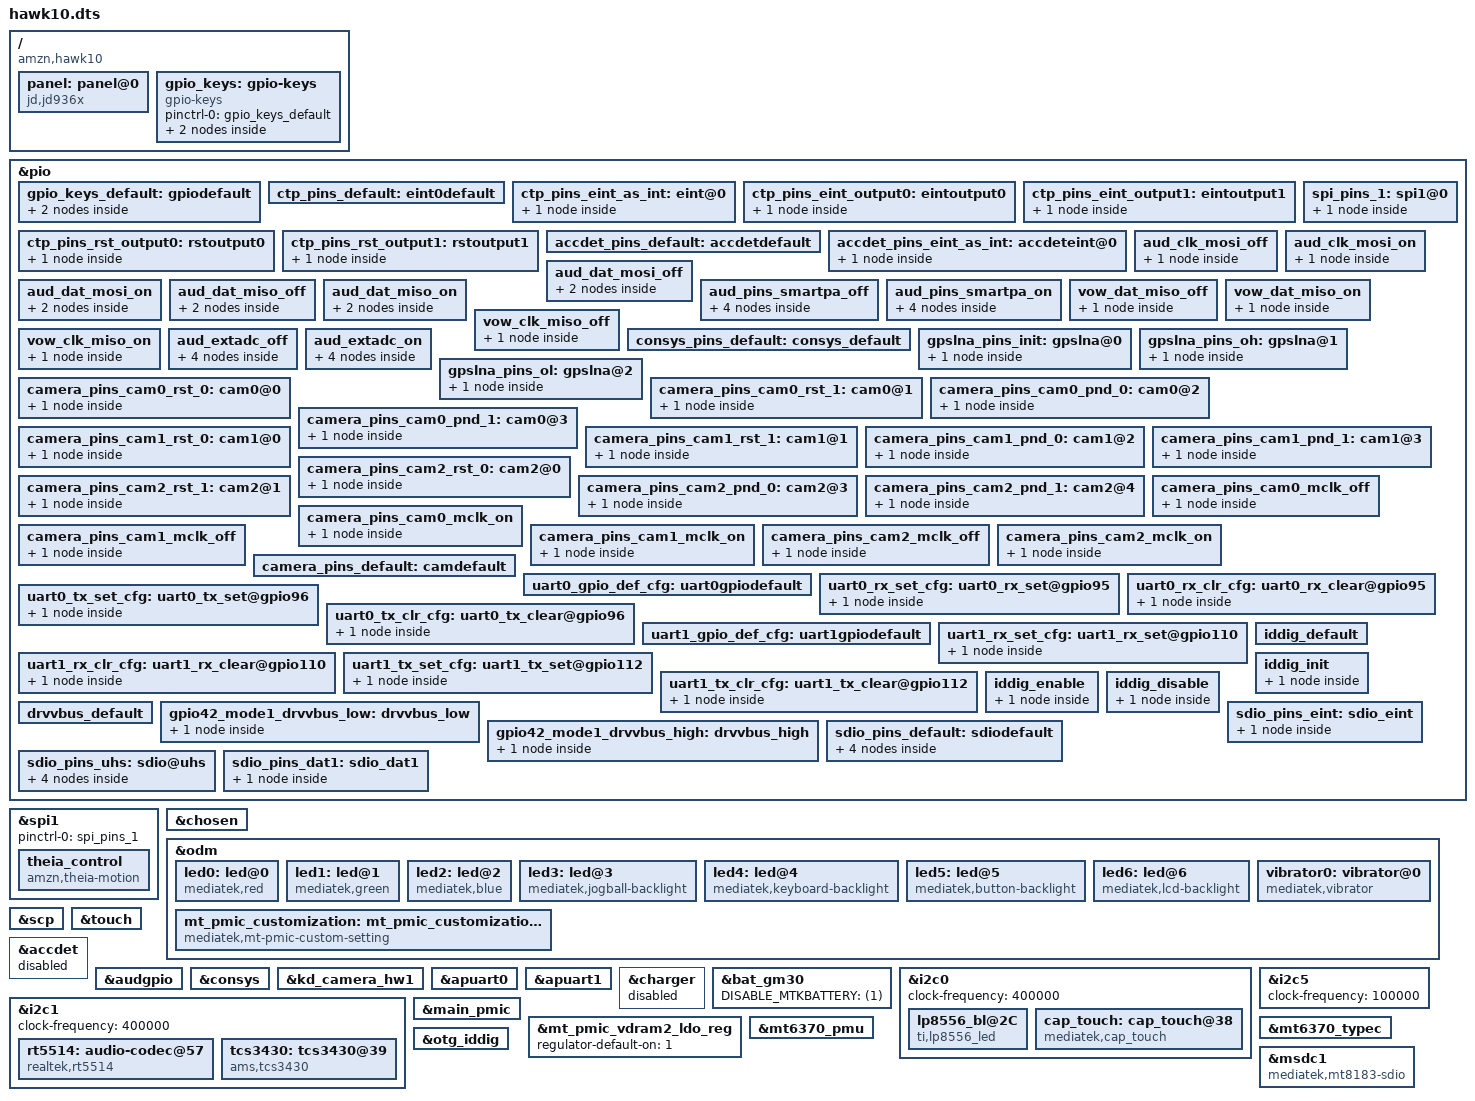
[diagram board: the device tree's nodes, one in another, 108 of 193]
/*
 * Copyright (C) 2018 MediaTek Inc.
 *
 * This program is free software; you can redistribute it and/or modify
 * it under the terms of the GNU General Public License version 2 as
 * published by the Free Software Foundation.
 *
 * This program is distributed in the hope that it will be useful,
 * but WITHOUT ANY WARRANTY; without even the implied warranty of
 * MERCHANTABILITY or FITNESS FOR A PARTICULAR PURPOSE.  See the
 * GNU General Public License for more details.  */

#include "mt8183.dts"
#include <hawk10/cust.dtsi>
#include <dt-bindings/clock/mt8183-clk.h>

/ {
	compatible = "amzn,hawk10";

	panel: panel@0 {
		compatible = "jd,jd936x";
		gpio_lcd_rst = <&pio 159 0>;
		gpio_bias_en = <&pio 176 0>;
		gpio_bl_en = <&pio 54 0>;
		status = "okay";
	};

	gpio_keys: gpio-keys {
		status = "okay";
		compatible = "gpio-keys";
		#address-cells = <1>;
		#size-cells = <0>;
		pinctrl-names = "default";
		pinctrl-0 = <&gpio_keys_default>;

		volumeup_button: button@0 {
			debounce_interval = <50>;
			wakeup-source;
			gpio-key,wakeup = <1>;
			gpios = <&pio 91 GPIO_ACTIVE_HIGH>;
			label = "volumeup";
			linux,input-type = <0x1>;
			linux,code = <115>;
		};

		volumedown_button: button@1 {
			debounce_interval = <50>;
			wakeup-source;
			gpio-key,wakeup = <1>;
			gpios = <&pio 92 GPIO_ACTIVE_HIGH>;
			label = "volumedown";
			linux,input-type = <0x1>;
			linux,code = <114>;
		};
	};

};

&pio {
	gpio_keys_default: gpiodefault {
		pins_cmd_dat_low {
			pinmux = <PINMUX_GPIO91__FUNC_GPIO91>,
			<PINMUX_GPIO92__FUNC_GPIO92>;
			input-enable;
			bias-pull-down = <MTK_PUPD_SET_R1R0_01>;
		};
		pins_cmd_dat_high {
			pinmux = <PINMUX_GPIO93__FUNC_GPIO93>;
			slew-rate = <1>;
			output-enable;
			output-high;
		};
	};
};

&spi1 {
	pinctrl-names = "default";
	pinctrl-0 = <&spi_pins_1>;
	status = "okay";

	theia_control: theia_control {
	compatible = "amzn,theia-motion";
		interrupt-parent = <&pio>;
		interrupts = <71 IRQ_TYPE_LEVEL_HIGH 0 0>;
		amzn,motion-int-gpio = <&pio 71 0>;
		amzn,motion-reset-gpio = <&pio 70 1>;
		amzn,motion-boot-gpio = <&pio 159 0>;
		amzn,motion-cs-gpio = <&pio 162 1>;
		amzn,motion-power-gpio = <&pio 4 1>;
		bootup-delay-ms = <1>;
		response_timeout_us = <1000>;
		spi-max-frequency = <6000000>;
		polling_buffer_size = <65531>;
		polling_per_second = <15>;
		seconds_to_sync = <10>;
		reg = <0>;
		status = "okay";
	};
};

/* chosen */
&chosen {
	bootargs = "console=tty0 console=ttyS0,921600n1 vmalloc=496M slub_max_order=0 slub_debug=OFZPU androidboot.hardware=mt8183 firmware_class.path=/vendor/firmware loop.max_part=7 musb_hdrc.mu3d_force_on=1";

	/* fpga may has no lk, we need to specify display info here */
	/* fb buffer is reserved using this dts by memory node above */

	atag,videolfb-fb_base_l = <0x5e605000>;
	atag,videolfb-fb_base_h = <0x0>;
	atag,videolfb-islcmfound = <1>;
	atag,videolfb-islcm_inited = <0>;
	atag,videolfb-fps= <6000>;
	atag,videolfb-vramSize= <0x017bb000>;
	atag,videolfb-lcmname= "otm1901a_fhd_dsi_vdo_tpv";
};

&odm {
	led0:led@0 {
		compatible = "mediatek,red";
		led_mode = <0>;
		data = <1>;
		pwm_config = <0 0 0 0 0>;
	};
	led1:led@1 {
		compatible = "mediatek,green";
		led_mode = <0>;
		data = <1>;
		pwm_config = <0 0 0 0 0>;
	};
	led2:led@2 {
		compatible = "mediatek,blue";
		led_mode = <0>;
		data = <1>;
		pwm_config = <0 0 0 0 0>;
	};
	led3:led@3 {
		compatible = "mediatek,jogball-backlight";
		led_mode = <0>;
		data = <1>;
		pwm_config = <0 0 0 0 0>;
	};
	led4:led@4 {
		compatible = "mediatek,keyboard-backlight";
		led_mode = <0>;
		data = <1>;
		pwm_config = <0 0 0 0 0>;
	};
	led5:led@5 {
		compatible = "mediatek,button-backlight";
		led_mode = <0>;
		data = <1>;
		pwm_config = <0 0 0 0 0>;
	};
	led6:led@6 {
		compatible = "mediatek,lcd-backlight";
		led_mode = <5>;
		data = <1>;
		pwm_config = <0 3 0 0 0>;
	};
	vibrator0:vibrator@0 {
		compatible = "mediatek,vibrator";
		vib_timer = <25>;
		vib_limit = <9>;
		vib_vol= <9>;
	};
	mt_pmic_customization: mt_pmic_customization@0 {
		compatible = "mediatek,mt-pmic-custom-setting";
		custom-reg = <0x1c32 0x1 0x7 0x0 /* LDO_VRF12_OP_EN */
			      0x18ba 0x1 0x1 0x0 /* RG_VPA_NDIS_EN */
		>;
		disable-modem = <1>;
	};


};

&scp {
	core_1 = "enable";
	scp_sramSize = <0x00080000>;     /* scp_A_sram_size */
};

/* TOUCH start */
&touch {
	vtouch-supply = <&mt_pmic_vmch_ldo_reg>;
	tpd-resolution = <800 1280>;
	use-tpd-button = <0>;
	tpd-key-num = <3>;
	tpd-key-local= <139 172 158 0>;
	tpd-key-dim-local = <145 1330 120 100 360 1330 120 100 600 1330 120 100 0 0 0 0>;
	tpd-max-touch-num = <5>;
	tpd-filter-enable = <1>;
	tpd-filter-pixel-density = <124>;
	tpd-filter-custom-prameters = <0 0 0 0 0 0 0 0 0 0 0 0>;
	tpd-filter-custom-speed = <0 0 0>;
	pinctrl-names = "default", "state_eint_as_int", "state_eint_output0", "state_eint_output1",
		"state_rst_output0", "state_rst_output1";
	pinctrl-0 = <&ctp_pins_default>;
	pinctrl-1 = <&ctp_pins_eint_as_int>;
	pinctrl-2 = <&ctp_pins_eint_output0>;
	pinctrl-3 = <&ctp_pins_eint_output1>;
	pinctrl-4 = <&ctp_pins_rst_output0>;
	pinctrl-5 = <&ctp_pins_rst_output1>;
	status = "okay";
};

&pio {
	ctp_pins_default: eint0default {
	};
	ctp_pins_eint_as_int: eint@0 {
		pins_cmd_dat {
			pins = <PINMUX_GPIO2__FUNC_GPIO2>;
			slew-rate = <0>;
			bias-disable;
		};
	};
	ctp_pins_eint_output0: eintoutput0 {
		pins_cmd_dat {
			pins = <PINMUX_GPIO2__FUNC_GPIO2>;
			slew-rate = <1>;
			output-low;
		};
	};
	ctp_pins_eint_output1: eintoutput1 {
		pins_cmd_dat {
			pins = <PINMUX_GPIO2__FUNC_GPIO2>;
			slew-rate = <1>;
			output-high;
		};
	};
	ctp_pins_rst_output0: rstoutput0 {
		pins_cmd_dat {
			pins = <PINMUX_GPIO158__FUNC_GPIO158>;
			slew-rate = <1>;
			output-low;
		};
	};
	ctp_pins_rst_output1: rstoutput1 {
		pins_cmd_dat {
			pins = <PINMUX_GPIO158__FUNC_GPIO158>;
			slew-rate = <1>;
			output-high;
		};
	};
	spi_pins_1: spi1@0{
		pins_spi{
			pinmux = <PINMUX_GPIO161__FUNC_SPI1_A_MI>,
				<PINMUX_GPIO162__FUNC_GPIO162>,
				<PINMUX_GPIO163__FUNC_SPI1_A_MO>,
				<PINMUX_GPIO164__FUNC_SPI1_A_CLK>;
			bias-disable;
		};
	};
};
/* TOUCH end */

/* accdet start */
&accdet {
	status = "disabled";
};
&pio {
	accdet_pins_default: accdetdefault {
	};
	accdet_pins_eint_as_int: accdeteint@0 {
		pins_cmd_dat {
			pins = <PINMUX_GPIO10__FUNC_GPIO10>;
			slew-rate = <0>;
			bias-disable;
		};
	};
};
/* accdet end */

/* AUDIO GPIO standardization */
&audgpio {
	pinctrl-names = "aud_clk_mosi_off",
			"aud_clk_mosi_on",
			"aud_dat_mosi_off",
			"aud_dat_mosi_on",
			"aud_dat_miso_off",
			"aud_dat_miso_on",
			"aud_smartpa_off",
			"aud_smartpa_on",
			"vow_dat_miso_off",
			"vow_dat_miso_on",
			"vow_clk_miso_off",
			"vow_clk_miso_on",
			"aud_extadc_off",
			"aud_extadc_on";
	pinctrl-0 = <&aud_clk_mosi_off>;
	pinctrl-1 = <&aud_clk_mosi_on>;
	pinctrl-2 = <&aud_dat_mosi_off>;
	pinctrl-3 = <&aud_dat_mosi_on>;
	pinctrl-4 = <&aud_dat_miso_off>;
	pinctrl-5 = <&aud_dat_miso_on>;
	pinctrl-6 = <&aud_pins_smartpa_off>;
	pinctrl-7 = <&aud_pins_smartpa_on>;
	pinctrl-8 = <&vow_dat_miso_off>;
	pinctrl-9 = <&vow_dat_miso_on>;
	pinctrl-10 = <&vow_clk_miso_off>;
	pinctrl-11 = <&vow_clk_miso_on>;
	pinctrl-12 = <&aud_extadc_off>;
	pinctrl-13 = <&aud_extadc_on>;
	status = "okay";
};

&pio {
	aud_clk_mosi_off: aud_clk_mosi_off {
		pins_cmd0_dat {
			pins = <PINMUX_GPIO136__FUNC_GPIO136>;
		};
	};

	aud_clk_mosi_on: aud_clk_mosi_on {
		pins_cmd0_dat {
			pins = <PINMUX_GPIO136__FUNC_AUD_CLK_MOSI>;
		};
	};

	aud_dat_mosi_off: aud_dat_mosi_off {
		pins_cmd1_dat {
			pins = <PINMUX_GPIO138__FUNC_GPIO138>;
		};
		pins_cmd2_dat {
			pins = <PINMUX_GPIO139__FUNC_GPIO139>;
		};
	};

	aud_dat_mosi_on: aud_dat_mosi_on {
		pins_cmd1_dat {
			pins = <PINMUX_GPIO138__FUNC_AUD_DAT_MOSI0>;
		};
		pins_cmd2_dat {
			pins = <PINMUX_GPIO139__FUNC_AUD_DAT_MOSI1>;
		};
	};

	aud_dat_miso_off: aud_dat_miso_off {
		pins_cmd1_dat {
			pins = <PINMUX_GPIO142__FUNC_GPIO142>;
		};
		pins_cmd2_dat {
			pins = <PINMUX_GPIO143__FUNC_GPIO143>;
		};
	};

	aud_dat_miso_on: aud_dat_miso_on {
		pins_cmd1_dat {
			pins = <PINMUX_GPIO142__FUNC_AUD_DAT_MISO0>;
		};
		pins_cmd2_dat {
			pins = <PINMUX_GPIO143__FUNC_AUD_DAT_MISO1>;
		};
	};

	aud_pins_smartpa_off: aud_pins_smartpa_off {
		pins_cmd0_dat {
			pins = <PINMUX_GPIO170__FUNC_GPIO170>;
		};
		pins_cmd1_dat {
			pins = <PINMUX_GPIO171__FUNC_GPIO171>;
		};
		pins_cmd2_dat {
			pins = <PINMUX_GPIO172__FUNC_GPIO172>;
		};
		pins_cmd3_dat {
			pins = <PINMUX_GPIO173__FUNC_GPIO173>;
		};
	};

	aud_pins_smartpa_on: aud_pins_smartpa_on {
		pins_cmd0_dat {
			pins = <PINMUX_GPIO170__FUNC_I2S1_BCK>;
		};
		pins_cmd1_dat {
			pins = <PINMUX_GPIO171__FUNC_I2S1_LRCK>;
		};
		pins_cmd2_dat {
			pins = <PINMUX_GPIO172__FUNC_I2S1_DO>;
		};
		pins_cmd3_dat {
			pins = <PINMUX_GPIO173__FUNC_I2S1_MCK>;
		};
	};

	vow_dat_miso_off: vow_dat_miso_off {
		pins_cmd1_dat {
			pins = <PINMUX_GPIO142__FUNC_GPIO142>;
		};
	};

	vow_dat_miso_on: vow_dat_miso_on {
		pins_cmd1_dat {
			pins = <PINMUX_GPIO142__FUNC_VOW_DAT_MISO>;
		};
	};

	vow_clk_miso_off: vow_clk_miso_off {
		pins_cmd3_dat {
			pins = <PINMUX_GPIO143__FUNC_GPIO143>;
		};
	};

	vow_clk_miso_on: vow_clk_miso_on {
		pins_cmd3_dat {
			pins = <PINMUX_GPIO143__FUNC_VOW_CLK_MISO>;
		};
	};

	aud_extadc_off: aud_extadc_off {
		pins_cmd0_dat {
			pins = <PINMUX_GPIO98__FUNC_GPIO98>;
		};
		pins_cmd1_dat {
			pins = <PINMUX_GPIO101__FUNC_GPIO101>;
		};
		pins_cmd2_dat {
			pins = <PINMUX_GPIO102__FUNC_GPIO102>;
		};
		pins_cmd3_dat {
			pins = <PINMUX_GPIO174__FUNC_GPIO174>;
		};
	};

	aud_extadc_on: aud_extadc_on {
		pins_cmd0_dat {
			pins = <PINMUX_GPIO98__FUNC_I2S2_BCK>;
		};
		pins_cmd1_dat {
			pins = <PINMUX_GPIO101__FUNC_I2S2_LRCK>;
		};
		pins_cmd2_dat {
			pins = <PINMUX_GPIO102__FUNC_I2S2_DI>;
		};
		pins_cmd3_dat {
			pins = <PINMUX_GPIO174__FUNC_I2S2_DI2>;
		};
	};
};

/* AUDIO end */

/* CONSYS GPIO standardization */
&pio {
	consys_pins_default: consys_default {
	};
	gpslna_pins_init: gpslna@0 {
		pins_cmd_dat {
			pins = <PINMUX_GPIO155__FUNC_GPIO155>;
			slew-rate = <0>;
			bias-disable;
			output-low;
		};
	};
	gpslna_pins_oh: gpslna@1 {
		pins_cmd_dat {
			pins = <PINMUX_GPIO155__FUNC_GPIO155>;
			slew-rate = <1>;
			output-high;
		};
	};
	gpslna_pins_ol: gpslna@2 {
		pins_cmd_dat {
			pins = <PINMUX_GPIO155__FUNC_GPIO155>;
			slew-rate = <1>;
			output-low;
		};
	};
};
&consys {
	pinctrl-names = "default", "gps_lna_state_init", "gps_lna_state_oh", "gps_lna_state_ol";
	pinctrl-0 = <&consys_pins_default>;
	pinctrl-1 = <&gpslna_pins_init>;
	pinctrl-2 = <&gpslna_pins_oh>;
	pinctrl-3 = <&gpslna_pins_ol>;
	status = "okay";
};
/* CONSYS end */

/* CAMERA GPIO standardization */
&pio {
	camera_pins_cam0_rst_0: cam0@0 {
		pins_cmd_dat {
			pins = <PINMUX_GPIO101__FUNC_GPIO101>;
			slew-rate = <1>; /*direction 0:in, 1:out*/
			output-low;/*direction out used only. output_low or high*/
		};
	};
	camera_pins_cam0_rst_1: cam0@1 {
		pins_cmd_dat {
			pins = <PINMUX_GPIO101__FUNC_GPIO101>;
			slew-rate = <1>;
			output-high;
		};
	};
	camera_pins_cam0_pnd_0: cam0@2 {
		pins_cmd_dat {
			pins = <PINMUX_GPIO97__FUNC_GPIO97>;
			slew-rate = <1>;
			output-low;
		};
	};
	camera_pins_cam0_pnd_1: cam0@3 {
		pins_cmd_dat {
			pins = <PINMUX_GPIO97__FUNC_GPIO97>;
			slew-rate = <1>;
			output-high;
		};
	};
	camera_pins_cam1_rst_0: cam1@0 {
		pins_cmd_dat {
			pins = <PINMUX_GPIO102__FUNC_GPIO102>;
			slew-rate = <1>; /*direction 0:in, 1:out*/
			output-low;/*direction out used only. output_low or high*/
		};
	};
	camera_pins_cam1_rst_1: cam1@1 {
		pins_cmd_dat {
			pins = <PINMUX_GPIO102__FUNC_GPIO102>;
			slew-rate = <1>;
			output-high;
		};
	};
	camera_pins_cam1_pnd_0: cam1@2 {
		pins_cmd_dat {
			pins = <PINMUX_GPIO98__FUNC_GPIO98>;
			slew-rate = <1>;
			output-low;
		};
	};
	camera_pins_cam1_pnd_1: cam1@3 {
		pins_cmd_dat {
			pins = <PINMUX_GPIO98__FUNC_GPIO98>;
			slew-rate = <1>;
			output-high;
		};
	};
	camera_pins_cam2_rst_0: cam2@0 {
		pins_cmd_dat {
			pins = <PINMUX_GPIO109__FUNC_GPIO109>;
			slew-rate = <1>;
			output-low;
		};
	};
	camera_pins_cam2_rst_1: cam2@1 {
		pins_cmd_dat {
			pins = <PINMUX_GPIO109__FUNC_GPIO109>;
			slew-rate = <1>;
			output-high;
		};
	};
	camera_pins_cam2_pnd_0: cam2@3 {
		pins_cmd_dat {
			pins = <PINMUX_GPIO107__FUNC_GPIO107>;
			slew-rate = <1>;
			output-low;
		};
	};
	camera_pins_cam2_pnd_1: cam2@4 {
		pins_cmd_dat {
			pins = <PINMUX_GPIO107__FUNC_GPIO107>;
			slew-rate = <1>;
			output-high;
		};
	};
	camera_pins_cam0_mclk_off: camera_pins_cam0_mclk_off {
		pins_cmd_dat {
			pins = <PINMUX_GPIO99__FUNC_GPIO99>;
		};
	};
	camera_pins_cam0_mclk_on: camera_pins_cam0_mclk_on {
		pins_cmd_dat {
			pins = <PINMUX_GPIO99__FUNC_CMMCLK0>;
		};
	};
	camera_pins_cam1_mclk_off: camera_pins_cam1_mclk_off {
		pins_cmd_dat {
			pins = <PINMUX_GPIO100__FUNC_GPIO100>;
		};
	};
	camera_pins_cam1_mclk_on: camera_pins_cam1_mclk_on {
		pins_cmd_dat {
			pins = <PINMUX_GPIO100__FUNC_CMMCLK1>;
		};
	};
	camera_pins_cam2_mclk_off: camera_pins_cam2_mclk_off {
		pins_cmd_dat {
			pins = <PINMUX_GPIO108__FUNC_GPIO108>;
		};
	};
	camera_pins_cam2_mclk_on: camera_pins_cam2_mclk_on {
		pins_cmd_dat {
			pins = <PINMUX_GPIO108__FUNC_CMMCLK2>;
		};
	};
	camera_pins_default: camdefault {
	};
};
&kd_camera_hw1 {
	pinctrl-names = "default",
			"cam0_rst0", "cam0_rst1",
			"cam0_pnd0", "cam0_pnd1",
			"cam1_rst0", "cam1_rst1",
			"cam1_pnd0", "cam1_pnd1",
			"cam2_rst0", "cam2_rst1",
			"cam2_pnd0", "cam2_pnd1",
			"cam0_mclk_off", "cam0_mclk_on",
			"cam1_mclk_off", "cam1_mclk_on",
			"cam2_mclk_off", "cam2_mclk_on";
	pinctrl-0 = <&camera_pins_default>;
	pinctrl-1 = <&camera_pins_cam0_rst_0>;
	pinctrl-2 = <&camera_pins_cam0_rst_1>;
	pinctrl-3 = <&camera_pins_cam0_pnd_0>;
	pinctrl-4 = <&camera_pins_cam0_pnd_1>;
	pinctrl-5 = <&camera_pins_cam1_rst_0>;
	pinctrl-6 = <&camera_pins_cam1_rst_1>;
	pinctrl-7 = <&camera_pins_cam1_pnd_0>;
	pinctrl-8 = <&camera_pins_cam1_pnd_1>;
	pinctrl-9 = <&camera_pins_cam2_rst_0>;
	pinctrl-10 = <&camera_pins_cam2_rst_1>;
	pinctrl-11 = <&camera_pins_cam2_pnd_0>;
	pinctrl-12 = <&camera_pins_cam2_pnd_1>;
	pinctrl-13 = <&camera_pins_cam0_mclk_off>;
	pinctrl-14 = <&camera_pins_cam0_mclk_on>;
	pinctrl-15 = <&camera_pins_cam1_mclk_off>;
	pinctrl-16 = <&camera_pins_cam1_mclk_on>;
	pinctrl-17 = <&camera_pins_cam2_mclk_off>;
	pinctrl-18 = <&camera_pins_cam2_mclk_on>;
	status = "okay";
};

/* UART GPIO */
&apuart0 {
	pinctrl-names = "uart0_gpio_default",
			"uart0_rx_set",
			"uart0_rx_clear",
			"uart0_tx_set",
			"uart0_tx_clear";
	pinctrl-0 = <&uart0_gpio_def_cfg>;
	pinctrl-1 = <&uart0_rx_set_cfg>;
	pinctrl-2 = <&uart0_rx_clr_cfg>;
	pinctrl-3 = <&uart0_tx_set_cfg>;
	pinctrl-4 = <&uart0_tx_clr_cfg>;
	status = "okay";
};

&apuart1 {
	pinctrl-names = "uart1_gpio_default",
			"uart1_rx_set",
			"uart1_rx_clear",
			"uart1_tx_set",
			"uart1_tx_clear";
	pinctrl-0 = <&uart1_gpio_def_cfg>;
	pinctrl-1 = <&uart1_rx_set_cfg>;
	pinctrl-2 = <&uart1_rx_clr_cfg>;
	pinctrl-3 = <&uart1_tx_set_cfg>;
	pinctrl-4 = <&uart1_tx_clr_cfg>;
	status = "okay";
};

&pio {
	/* UART GPIO Settings - Start */
	/* UART0: rx set, rx clear, tx clear, tx clear*/
	uart0_gpio_def_cfg:uart0gpiodefault {

	};
	uart0_rx_set_cfg:uart0_rx_set@gpio95 {
		pins_cmd_dat {
			pins = <PINMUX_GPIO95__FUNC_URXD0>;
		};
	};
	uart0_rx_clr_cfg:uart0_rx_clear@gpio95 {
		pins_cmd_dat {
			pins = <PINMUX_GPIO95__FUNC_GPIO95>;
			slew-rate = <1>;
			output-high;
		};
	};
	uart0_tx_set_cfg:uart0_tx_set@gpio96 {
		pins_cmd_dat {
			pins = <PINMUX_GPIO96__FUNC_UTXD0>;
		};
	};
	uart0_tx_clr_cfg:uart0_tx_clear@gpio96 {
		pins_cmd_dat {
			pins = <PINMUX_GPIO96__FUNC_GPIO96>;
			slew-rate = <1>;
			output-high;
		};
	};

	/* UART1: rx set, rx clear, tx clear, tx clear*/
	uart1_gpio_def_cfg:uart1gpiodefault {

	};
	uart1_rx_set_cfg:uart1_rx_set@gpio110 {
		pins_cmd_dat {
			pins = <PINMUX_GPIO110__FUNC_URXD1>;
		};
	};
	uart1_rx_clr_cfg:uart1_rx_clear@gpio110 {
		pins_cmd_dat {
			pins = <PINMUX_GPIO110__FUNC_GPIO110>;
			slew-rate = <1>;
			output-high;
		};
	};
	uart1_tx_set_cfg:uart1_tx_set@gpio112 {
		pins_cmd_dat {
			pins = <PINMUX_GPIO112__FUNC_UTXD1>;
		};
	};
	uart1_tx_clr_cfg:uart1_tx_clear@gpio112 {
		pins_cmd_dat {
			pins = <PINMUX_GPIO112__FUNC_GPIO112>;
			slew-rate = <1>;
			output-high;
		};
	};
};/* UART GPIO end */

&charger {
	status = "disabled";
};

/delete-node/ &lk_charger;

&bat_gm30 {
	DISABLE_MTKBATTERY = <(1)>;
};

&i2c0 {
	clock-frequency = <400000>;
	status = "okay";

	lp8556_bl@2C {
		compatible = "ti,lp8556_led";
		reg = <0x2C>;
		mode = <2>;
		/* dev-ctrl should be 0x7 for abc123 (0x3 for factory), set 0x05 for proto temporarily
		 * LP8557I have no LP8557_PWM_FILTER bit, it's different from LP8557E
		 */
		dev-ctrl = /bits/ 8 <0x05>; /* (LP8557_I2C_CONFIG | LP8557_DISABLE_LEDS) */
		init-brt = /bits/ 8 <0x64>;

		eeprom_data = /bits/ 8 <0x14 0xCF  /* 4V OV, 4 output LED string enabled */
					0x13 0x01  /* Boost frequency @1MHz */
					0x11 0x05  /* Full scale 20 mA */
					0x12 0x2B  /* 19.5 kHz */ /* bypass if it is reset value */
					0x15 0x42  /* Light smoothing, 100 ms */ /* bypass if it is reset value */
					0x16 0xA0>;/* Max boost voltage 25V, enable adaptive voltage */
	};

	cap_touch:cap_touch@38 {
		compatible = "mediatek,cap_touch";
		reg = <0x38>;
		interrupt-parent = <&pio>;
		interrupts = <2 IRQ_TYPE_LEVEL_LOW 2 0>;
		int-gpio = <&pio 2 0>;
		rst-gpio = <&pio 158 0>;
	};
};

&i2c1 {
	clock-frequency = <400000>;
	status = "okay";

	rt5514: audio-codec@57 {
		compatible = "realtek,rt5514";
		#sound-dai-cells = <0>;
		reg = <0x57>;
		interrupt-parent = <&pio>;
		interrupts = <0 IRQ_TYPE_LEVEL_HIGH 0 0>;
	};

	tcs3430: tcs3430@39 {
		compatible = "ams,tcs3430";
		reg = <0x39>;
		interrupt-parent = <&pio>;
		interrupts = <9 IRQ_TYPE_LEVEL_LOW 0 0>;
		als_name = "tcs3430_als";
		persist = <2>;
		als_gain = <1>;
		als_auto_gain = <1>;
		als_deltap = <10>;
		als_time = <72>;
		als_can_wake = <0>;
	};
};

&i2c5 {
	clock-frequency = <100000>;
	status = "okay";
};

&main_pmic {
	interrupt-parent = <&pio>;
	interrupts = <182 IRQ_TYPE_LEVEL_HIGH 190 0>;
	status = "okay";
};

&mt_pmic_vdram2_ldo_reg {
	regulator-default-on = <1>;
};

&mt6370_pmu {
	mt6370,intr_gpio_num = <10>; /* direct defined GPIO num */
	mt6370,intr_gpio = <&pio 10 0x0>;
};

&mt6370_typec {
	mt6370pd,intr_gpio_num = <41>; /* direct defined GPIO num */
	mt6370pd,intr_gpio = <&pio 41 0x0>;
};

/* USB Setting -Start */
&pio {
	iddig_default: iddig_default {
	};
	iddig_init: iddig_init {
		pins_cmd_dat {
			pins = <PINMUX_GPIO41__FUNC_IDDIG>;
			input-enable;
			slew-rate = <0>;
			bias-pull-up = <MTK_PUPD_SET_R1R0_01>;
		};
	};
	iddig_enable: iddig_enable {
		pins_cmd_dat {
			pins = <PINMUX_GPIO41__FUNC_IDDIG>;
			input-enable;
			slew-rate = <0>;
			bias-pull-up = <MTK_PUPD_SET_R1R0_01>;
		};
	};
	iddig_disable: iddig_disable {
		pins_cmd_dat {
			pins = <PINMUX_GPIO41__FUNC_GPIO41>;
			input-disable;
			slew-rate = <1>;
			output-low;
		};
	};
};
&pio {
	drvvbus_default: drvvbus_default {
	};

	gpio42_mode1_drvvbus_low: drvvbus_low {
		pins_cmd_dat {
			pins = <PINMUX_GPIO42__FUNC_GPIO42>;
			slew-rate = <1>;
			output-low;
		};
	};
	gpio42_mode1_drvvbus_high: drvvbus_high {
		pins_cmd_dat {
			pins = <PINMUX_GPIO42__FUNC_GPIO42>;
			slew-rate = <1>;
			output-high;
		};
	};
};
&otg_iddig {
	pinctrl-names = "iddig_default", "iddig_init", "iddig_enable", "iddig_disable",
							"drvvbus_default", "drvvbus_low", "drvvbus_high";
	pinctrl-0 = <&iddig_default>;
	pinctrl-1 = <&iddig_init>;
	pinctrl-2 = <&iddig_enable>;
	pinctrl-3 = <&iddig_disable>;
	pinctrl-4 = <&drvvbus_default>;
	pinctrl-5 = <&gpio42_mode1_drvvbus_low>;
	pinctrl-6 = <&gpio42_mode1_drvvbus_high>;
	status = "okay";
};

&msdc1 {
	compatible = "mediatek,mt8183-sdio";
	reg = <0x0 0x11240000 0x0 0x10000>,
	    <0 0x11e10000 0 0x1000>;
	clocks = <&infracfg_ao INFRACFG_AO_MSDC1_SCK_CG>,
	       <&infracfg_ao INFRACFG_AO_MSDC1_CG>;
	clock-names = "source", "hclk";
	status = "okay";
	eint-gpios = <&pio 34 GPIO_ACTIVE_HIGH>;
	bus-width = <4>;
	max-frequency = <100000000>;
	cap-sd-highspeed;
	sd-uhs-sdr50;
	sd-uhs-sdr104;
	pinctrl-names = "state_eint", "default", "state_uhs", "state_dat1";
	pinctrl-0 = <&sdio_pins_eint>;
	pinctrl-1 = <&sdio_pins_default>;
	pinctrl-2 = <&sdio_pins_uhs>;
	pinctrl-3 = <&sdio_pins_dat1>;
	keep-power-in-suspend;
	enable-sdio-wakeup;
	cap-sdio-irq;
	non-removable;
	vmmc-supply = <&mt_pmic_vmch_ldo_reg>;
	vqmmc-supply = <&mt_pmic_vmc_ldo_reg>;
};

&pio {
	sdio_pins_eint: sdio_eint {
		pins_dat1 {
			pinmux = <PINMUX_GPIO34__FUNC_GPIO34>;
			drive-strength = <4>;
			bias-pull-up = <MTK_PUPD_SET_R1R0_10>;
			output-high;
		};
	};

	sdio_pins_default: sdiodefault {
		pins_cmd_dat {
			pinmux = <PINMUX_GPIO31__FUNC_MSDC1_CMD>,
			       <PINMUX_GPIO32__FUNC_MSDC1_DAT0>,
			       <PINMUX_GPIO34__FUNC_MSDC1_DAT1>,
			       <PINMUX_GPIO33__FUNC_MSDC1_DAT2>,
			       <PINMUX_GPIO30__FUNC_MSDC1_DAT3>;
			drive-strength = <8>;
			bias-pull-up = <MTK_PUPD_SET_R1R0_01>;
			output-high;
		};

		pins_clk {
			pinmux = <PINMUX_GPIO29__FUNC_MSDC1_CLK>;
			drive-strength = <8>;
			bias-pull-down = <MTK_PUPD_SET_R1R0_10>;
			output-low;
		};

		pins_pmu {
			pinmux = <PINMUX_GPIO67__FUNC_GPIO67>;
			bias-pull-up;
			output-high;
		};

		pins_dev_rst {
			pinmux = <PINMUX_GPIO68__FUNC_GPIO68>;
			bias-pull-up;
			output-high;
		};
	};

	sdio_pins_uhs: sdio@uhs {
		pins_cmd_dat {
			pinmux = <PINMUX_GPIO31__FUNC_MSDC1_CMD>,
			       <PINMUX_GPIO32__FUNC_MSDC1_DAT0>,
			       <PINMUX_GPIO34__FUNC_MSDC1_DAT1>,
			       <PINMUX_GPIO33__FUNC_MSDC1_DAT2>,
			       <PINMUX_GPIO30__FUNC_MSDC1_DAT3>;
			drive-strength = <8>;
			bias-pull-up = <MTK_PUPD_SET_R1R0_10>;
			output-high;
		};

		pins_clk {
			pinmux = <PINMUX_GPIO29__FUNC_MSDC1_CLK>;
			drive-strength = <8>;
			bias-pull-down = <MTK_PUPD_SET_R1R0_10>;
			output-low;
		};

		pins_pmu {
			pinmux = <PINMUX_GPIO67__FUNC_GPIO67>;
			bias-pull-up;
			output-high;
		};

		pins_dev_rst {
			pinmux = <PINMUX_GPIO68__FUNC_GPIO68>;
			bias-pull-up;
			output-high;
		};
	};

	sdio_pins_dat1: sdio_dat1 {
		pins_dat1 {
			pinmux = <PINMUX_GPIO34__FUNC_MSDC1_DAT1>;
			drive-strength = <4>;
			bias-pull-up = <MTK_PUPD_SET_R1R0_10>;
			output-high;
		};
	};
};

/* USB Setting -End */

/*End of this file, DO NOT ADD ANYTHING HERE*/
